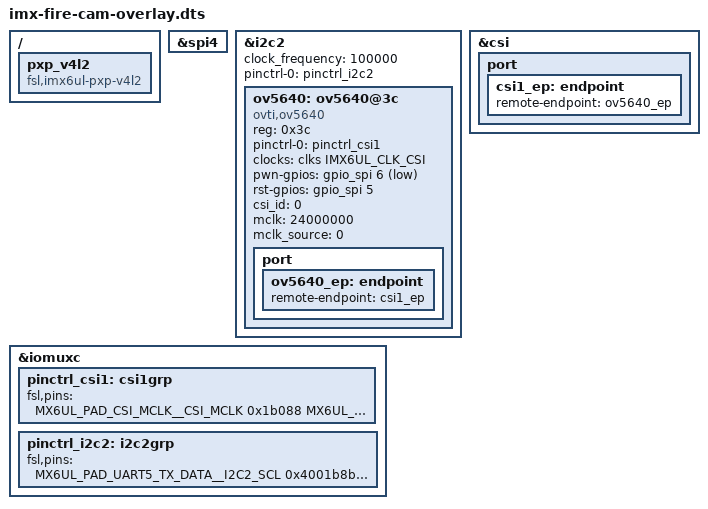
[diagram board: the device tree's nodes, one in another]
/*
 * Copyright (C) 2019 - All Rights Reserved by 
 * filename : imx-fire-uart3-overlay.dts
 * brief : Device Tree overlay for EBF6ull uart3 device
 * author : embedfire
 * date : 2019-11-19 
 * version : A001
 */
 
/dts-v1/;
/plugin/;

#include "../imx6ul-pinfunc.h"
#include "../imx6ull-pinfunc.h"
#include "dt-bindings/gpio/gpio.h"
#include "dt-bindings/clock/imx6ul-clock.h"
#include "../imx6ull-pinfunc-snvs.h"
/ {
	fragment@0 {
		target = <&spi4>;		
		__overlay__ {
			status = "okay";
		};
	};

     fragment@1 {
        target=<&i2c2>;
        __overlay__ {
					clock_frequency = <100000>;
					pinctrl-names = "default";
					pinctrl-0 = <&pinctrl_i2c2>;
					status = "okay"; 
					#address-cells = <1>;
					#size-cells = <0>;        
					ov5640: ov5640@3c {
						compatible = "ovti,ov5640";
						reg = <0x3c>;
						pinctrl-names = "default";
						pinctrl-0 = <&pinctrl_csi1>;
						clocks = <&clks IMX6UL_CLK_CSI>;
						clock-names = "csi_mclk";
						pwn-gpios = <&gpio_spi 6 1>;
						rst-gpios = <&gpio_spi 5 0>;
						csi_id = <0>;
						mclk = <24000000>;
						mclk_source = <0>;
						status = "okay";    
						port {
							ov5640_ep: endpoint {
								remote-endpoint = <&csi1_ep>;
							};
						};
					};          
        };
     };
		fragment@2 {
			target=<&iomuxc>;
			__overlay__ {
						pinctrl_csi1: csi1grp {
							fsl,pins = <
								MX6UL_PAD_CSI_MCLK__CSI_MCLK		0x1b088
								MX6UL_PAD_CSI_PIXCLK__CSI_PIXCLK	0x1b088
								MX6UL_PAD_CSI_VSYNC__CSI_VSYNC		0x1b088
								MX6UL_PAD_CSI_HSYNC__CSI_HSYNC		0x1b088
								MX6UL_PAD_CSI_DATA00__CSI_DATA02	0x1b088
								MX6UL_PAD_CSI_DATA01__CSI_DATA03	0x1b088
								MX6UL_PAD_CSI_DATA02__CSI_DATA04	0x1b088
								MX6UL_PAD_CSI_DATA03__CSI_DATA05	0x1b088
								MX6UL_PAD_CSI_DATA04__CSI_DATA06	0x1b088
								MX6UL_PAD_CSI_DATA05__CSI_DATA07	0x1b088
								MX6UL_PAD_CSI_DATA06__CSI_DATA08	0x1b088
								MX6UL_PAD_CSI_DATA07__CSI_DATA09	0x1b088
							>;
					};

					pinctrl_i2c2: i2c2grp {
						fsl,pins = <
							MX6UL_PAD_UART5_TX_DATA__I2C2_SCL 0x4001b8b0
							MX6UL_PAD_UART5_RX_DATA__I2C2_SDA 0x4001b8b0
						>;
					};
			};
		};
		fragment@3 {
			target = <&csi>;
			__overlay__ {
				status = "okay";  /* 摄像头总线使能 */

				port {
					csi1_ep: endpoint {
						remote-endpoint = <&ov5640_ep>;
					};
				};				
			};		
		};

		fragment@4 {
            target-path = "/";
            __overlay__ {
				pxp_v4l2 {
					compatible = "fsl,imx6ul-pxp-v4l2", "fsl,imx6sx-pxp-v4l2", "fsl,imx6sl-pxp-v4l2";
					status = "okay";
					};
			};
		};
};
